VERSION ""

NS_ :

BS_:

BU_: XXX

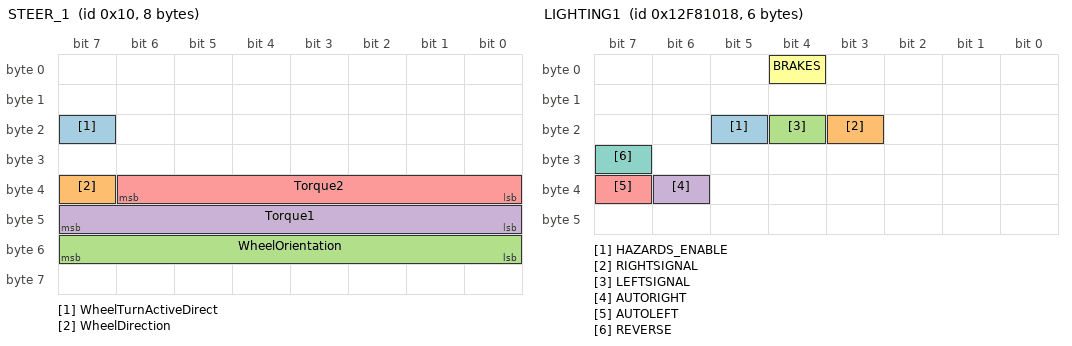
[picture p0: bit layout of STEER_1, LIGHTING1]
BO_ 16 STEER_1: 8 XXX
 SG_ WheelTurnActiveDirect : 23|1@0+ (1,0) [0|255] "" XXX
 SG_ WheelDirection : 39|1@0+ (1,0) [0|1] "" XXX
 SG_ WheelOrientation : 55|8@0+ (1,0) [0|255] "" XXX
 SG_ Torque1 : 40|8@1+ (1,0) [0|255] "" XXX
 SG_ Torque2 : 38|7@0+ (1,0) [0|127] "" XXX

BO_ 516 GAS: 8 XXX
 SG_ UserGasPosition : 1|18@0+ (1,0) [0|65535] "" XXX

BO_ 125 BRAKE1: 8 XXX
 SG_ PedalPosition : 7|16@0+ (1,0) [0|65535] "" XXX

BO_ 318246936 LIGHTING1: 6 XXX
 SG_ HAZARDS_ENABLE : 21|1@0+ (1,0) [0|1] "" XXX
 SG_ RIGHTSIGNAL : 19|1@0+ (1,0) [0|1] "" XXX
 SG_ LEFTSIGNAL : 20|1@0+ (1,0) [0|3] "" XXX
 SG_ AUTORIGHT : 38|1@0+ (1,0) [0|1] "" XXX
 SG_ AUTOLEFT : 39|1@0+ (1,0) [0|1] "" XXX
 SG_ BRAKES : 4|1@0+ (1,0) [0|1] "" XXX
 SG_ REVERSE : 31|1@0+ (1,0) [0|1] "" XXX

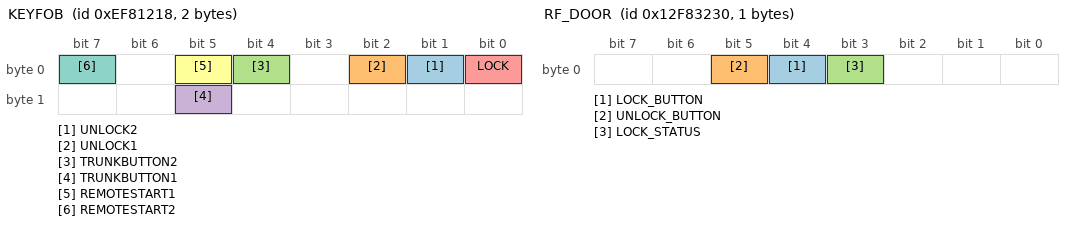
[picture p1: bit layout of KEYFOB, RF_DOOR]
BO_ 251138584 KEYFOB: 2 XXX
 SG_ UNLOCK2 : 1|1@0+ (1,0) [0|1] "" XXX
 SG_ UNLOCK1 : 2|1@0+ (1,0) [0|1] "" XXX
 SG_ TRUNKBUTTON2 : 4|1@0+ (1,0) [0|1] "" XXX
 SG_ TRUNKBUTTON1 : 13|1@0+ (1,0) [0|1] "" XXX
 SG_ LOCK : 0|1@0+ (1,0) [0|1] "" XXX
 SG_ REMOTESTART1 : 5|1@0+ (1,0) [0|1] "" XXX
 SG_ REMOTESTART2 : 7|1@0+ (1,0) [0|1] "" XXX

BO_ 318255664 RF_DOOR: 1 XXX
 SG_ LOCK_BUTTON : 4|1@0+ (1,0) [0|1] "" XXX
 SG_ UNLOCK_BUTTON : 5|1@0+ (1,0) [0|1] "" XXX
 SG_ LOCK_STATUS : 3|1@0+ (1,0) [0|1] "" XXX

BO_ 318255408 DOOR_STATUS2: 8 XXX

BO_ 184057368 LIGHTING2: 3 XXX

BO_ 318264400 LIGHTING3: 8 XXX
 SG_ PARKING_LIGHTS : 6|1@0+ (1,0) [0|1] "" XXX

BO_ 184029464 LIGHTING4: 6 XXX

BO_ 184053784 LIGHTING_STALK1: 3 XXX

BO_ 318259736 RR_DOOR: 1 XXX
 SG_ LOCK_STATUS : 7|1@0+ (1,0) [0|1] "" XXX

BO_ 318288034 HEATED_SEATS: 2 XXX
 SG_ PASS_SEAT : 2|2@0+ (1,0) [0|3] "" XXX
 SG_ DRIVER_SEAT : 6|2@0+ (1,0) [0|3] "" XXX

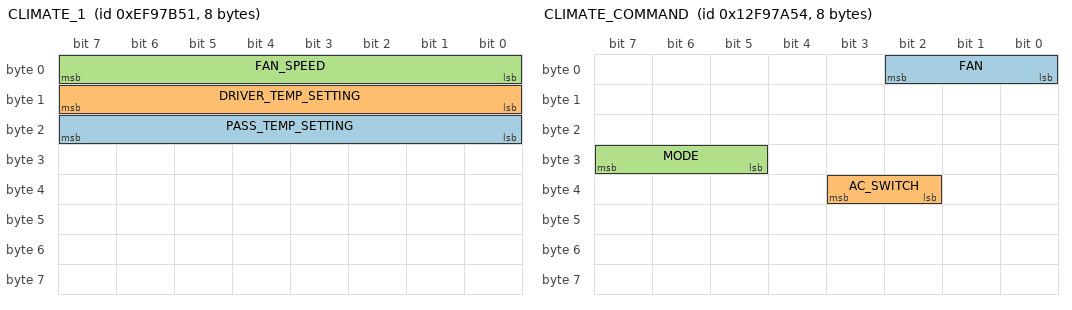
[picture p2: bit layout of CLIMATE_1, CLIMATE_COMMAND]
BO_ 251231057 CLIMATE_1: 8 XXX
 SG_ PASS_TEMP_SETTING : 16|8@1+ (1,0) [0|255] "" XXX
 SG_ DRIVER_TEMP_SETTING : 8|8@1+ (1,0) [0|255] "" XXX
 SG_ FAN_SPEED : 0|8@1+ (1,0) [0|255] "" XXX

BO_ 251142168 DOOR_LOCKS: 1 XXX
 SG_ LOCKACTION_STATUS : 7|2@0+ (1,0) [0|1] "" XXX

BO_ 318339668 CLIMATE_COMMAND: 8 XXX
 SG_ FAN : 0|3@1+ (1,0) [0|7] "" XXX
 SG_ AC_SWITCH : 34|2@1+ (1,0) [0|3] "" XXX
 SG_ MODE : 31|3@0+ (1,0) [0|7] "" XXX

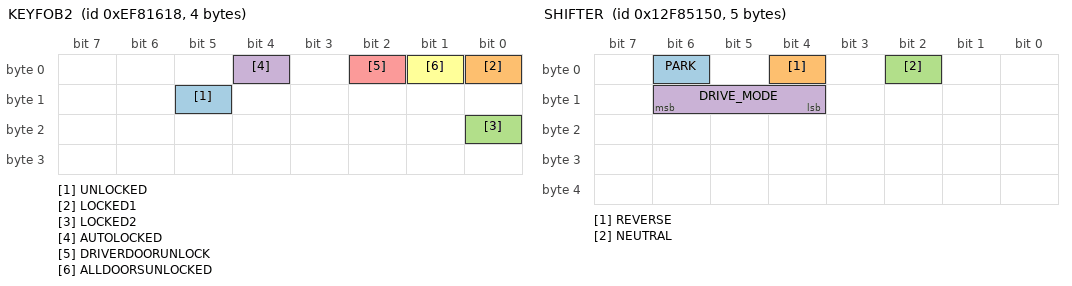
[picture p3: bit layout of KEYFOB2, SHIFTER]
BO_ 251139608 KEYFOB2: 4 XXX
 SG_ UNLOCKED : 13|1@0+ (1,0) [0|1] "" XXX
 SG_ LOCKED1 : 0|1@0+ (1,0) [0|1] "" XXX
 SG_ LOCKED2 : 16|1@0+ (1,0) [0|1] "" XXX
 SG_ AUTOLOCKED : 4|1@0+ (1,0) [0|1] "" XXX
 SG_ DRIVERDOORUNLOCK : 2|1@0+ (1,0) [0|1] "" XXX
 SG_ ALLDOORSUNLOCKED : 1|1@0+ (1,0) [0|1] "" XXX

BO_ 318260272 FRONT_WINDOWS: 2 XXX
 SG_ RF_WINDOWSTATE : 14|1@0+ (1,0) [0|1] "" XXX
 SG_ LF_WINDOWSTATE : 15|1@0+ (1,0) [0|1] "" XXX

BO_ 318263376 CONSOLE_SWITCHES: 6 XXX
 SG_ ECO_SWITCH : 29|1@0+ (1,0) [0|1] "" XXX
 SG_ ENGINE_RPM : 15|16@0+ (1,0) [0|65535] "" XXX

BO_ 318263632 SHIFTER: 5 XXX
 SG_ PARK : 6|1@0+ (1,0) [0|1] "" XXX
 SG_ REVERSE : 4|1@0+ (1,0) [0|1] "" XXX
 SG_ NEUTRAL : 2|1@0+ (1,0) [0|1] "" XXX
 SG_ DRIVE_MODE : 14|3@0+ (1,0) [0|7] "" XXX

BO_ 318337360 STEERING: 3 XXX

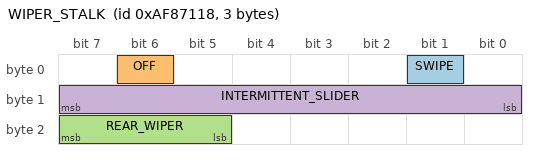
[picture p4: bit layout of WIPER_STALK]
BO_ 184054040 WIPER_STALK: 3 XXX
 SG_ SWIPE : 1|1@0+ (1,0) [0|1] "" XXX
 SG_ OFF : 6|1@0+ (1,0) [0|1] "" XXX
 SG_ REAR_WIPER : 23|3@0+ (1,0) [0|7] "" XXX
 SG_ INTERMITTENT_SLIDER : 15|8@0+ (1,0) [0|255] "" XXX

CM_ SG_ 16 WheelTurnActiveDirect "0-wheel going ccw,1-wheel going cw";
CM_ SG_ 16 WheelDirection "0-left,1-right. ";
CM_ SG_ 318255664 LOCK_STATUS "LOCKED = 0, UNLOCKED = 1";
CM_ SG_ 318264400 PARKING_LIGHTS "0 = OFF, 1 = ON";
CM_ SG_ 318259736 LOCK_STATUS "LOCKED = 0, UNLOCKED = 1";
CM_ SG_ 318288034 PASS_SEAT "0 = OFF, 1 = HIGH, 2 = MED, 3 = LO";
CM_ SG_ 318288034 DRIVER_SEAT "0 = OFF, 1 = HIGH, 2 = MED, 3 = LO";
CM_ SG_ 251231057 PASS_TEMP_SETTING "04 = HIGH, 08 = LO";
CM_ SG_ 251231057 DRIVER_TEMP_SETTING "04 = HIGH, 08 = LO";
CM_ SG_ 251231057 FAN_SPEED "en = current n setting, 6n = going to n setting";
CM_ SG_ 251142168 LOCKACTION_STATUS "0 = IDLE, 1 = UNLOCKING, 2 = LOCKING";
CM_ SG_ 318339668 MODE "5 = FACE, 4 = MIX, 3 = FLOOR, 2 = FLOOR_DEFROST";
CM_ SG_ 251139608 AUTOLOCKED "1 = CAR AUTOLOCKED";
CM_ SG_ 318260272 RF_WINDOWSTATE "1 = CLOSED, 0 = OPEN";
CM_ SG_ 318260272 LF_WINDOWSTATE "1 = CLOSED, 0 = OPEN";
CM_ SG_ 318263632 DRIVE_MODE "0 = DRIVE, 4 = S, 1 = L";
CM_ SG_ 184054040 REAR_WIPER "0 = OFF, 4 = INT, 1 = ON";
